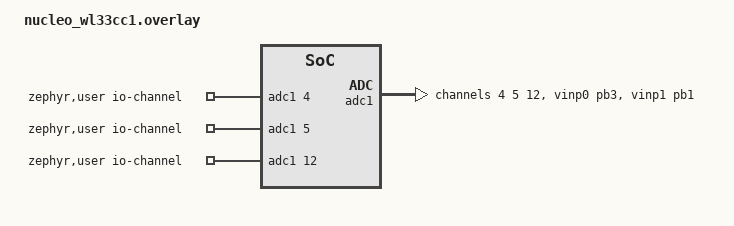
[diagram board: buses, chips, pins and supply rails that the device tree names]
/*
 * Copyright (c) 2026 Anders Frandsen <anfran@anfran.dk>
 *
 * SPDX-License-Identifier: Apache-2.0
 */

/ {
	zephyr,user {
		io-channels = <&adc1 4>, <&adc1 5>, <&adc1 12>;
	};
};

&adc1 {
	status = "okay";

	pinctrl-0 = <&adc1_vinp0_pb3 &adc1_vinp1_pb1>;
	pinctrl-names = "default";
	#address-cells = <1>;
	#size-cells = <0>;

	channel@4 {
		reg = <4>;
		zephyr,gain = "ADC_GAIN_1";
		zephyr,reference = "ADC_REF_INTERNAL";
		zephyr,acquisition-time = <ADC_ACQ_TIME_DEFAULT>;
		zephyr,resolution = <12>;
	};

	channel@5 {
		reg = <5>;
		zephyr,gain = "ADC_GAIN_1";
		zephyr,reference = "ADC_REF_INTERNAL";
		zephyr,acquisition-time = <ADC_ACQ_TIME_DEFAULT>;
		zephyr,resolution = <12>;
	};

	channel@c {
		reg = <12>;
		zephyr,gain = "ADC_GAIN_1";
		zephyr,reference = "ADC_REF_INTERNAL";
		zephyr,acquisition-time = <ADC_ACQ_TIME_DEFAULT>;
		zephyr,resolution = <12>;
	};
};
